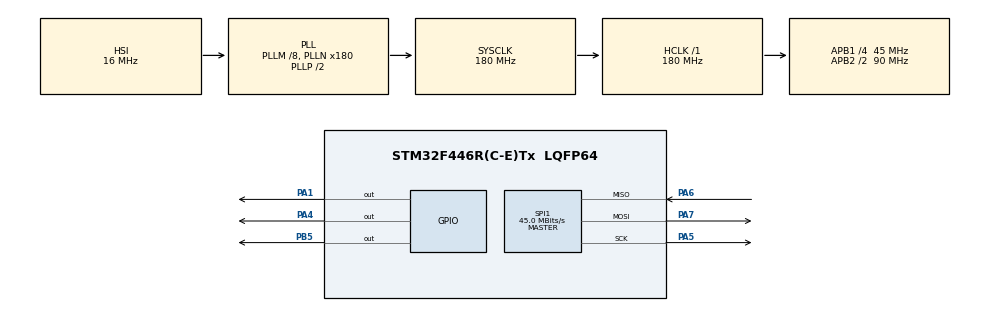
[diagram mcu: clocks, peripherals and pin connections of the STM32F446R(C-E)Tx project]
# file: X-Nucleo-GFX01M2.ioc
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Mcu.Family=STM32F4
Mcu.Name=STM32F446R(C-E)Tx
Mcu.Package=LQFP64
NVIC.PriorityGroup=NVIC_PRIORITYGROUP_4
PA1.GPIO_Speed=GPIO_SPEED_FREQ_VERY_HIGH
PA1.PinState=GPIO_PIN_SET
PA1.Signal=GPIO_Output
PA13.Mode=Serial_Wire
PA13.Signal=SYS_JTMS-SWDIO
PA14.Mode=Serial_Wire
PA14.Signal=SYS_JTCK-SWCLK
PA4.GPIO_Speed=GPIO_SPEED_FREQ_VERY_HIGH
PA4.Signal=GPIO_Output
PA5.Mode=Full_Duplex_Master
PA5.Signal=SPI1_SCK
PA6.Mode=Full_Duplex_Master
PA6.Signal=SPI1_MISO
PA7.Mode=Full_Duplex_Master
PA7.Signal=SPI1_MOSI
PB5.GPIO_Speed=GPIO_SPEED_FREQ_VERY_HIGH
PB5.PinState=GPIO_PIN_SET
PB5.Signal=GPIO_Output
ProjectManager.HeapSize=0x200
ProjectManager.StackSize=0x400
ProjectManager.TargetToolchain=MDK-ARM V5.32
RCC.AHBFreq_Value=180000000
RCC.APB1CLKDivider=RCC_HCLK_DIV4
RCC.APB1Freq_Value=45000000
RCC.APB1TimFreq_Value=90000000
RCC.APB2CLKDivider=RCC_HCLK_DIV2
RCC.APB2Freq_Value=90000000
RCC.APB2TimFreq_Value=180000000
RCC.CortexFreq_Value=180000000
RCC.HCLKFreq_Value=180000000
RCC.PLLM=8
RCC.PLLN=180
RCC.SYSCLKFreq_VALUE=180000000
RCC.SYSCLKSource=RCC_SYSCLKSOURCE_PLLCLK
RCC.USBFreq_Value=180000000
RCC.VCOOutputFreq_Value=360000000
SPI1.BaudRatePrescaler=SPI_BAUDRATEPRESCALER_2
SPI1.CalculateBaudRate=45.0 MBits/s
SPI1.Direction=SPI_DIRECTION_2LINES
SPI1.Mode=SPI_MODE_MASTER
SPI1.VirtualType=VM_MASTER
board=custom

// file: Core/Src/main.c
/* USER CODE BEGIN Header */
/**
  ******************************************************************************
  * @file           : main.c
  * @brief          : Main program body
  ******************************************************************************
  * @attention
  *
  * Copyright (c) 2026 STMicroelectronics.
  * All rights reserved.
  *
  * This software is licensed under terms that can be found in the LICENSE file
  * in the root directory of this software component.
  * If no LICENSE file comes with this software, it is provided AS-IS.
  *
  ******************************************************************************
  */
/* USER CODE END Header */
#include "main.h"
#include "spi.h"
#include "gpio.h"

/* USER CODE BEGIN Includes */
#include "st7789h2.h"
/* USER CODE END Includes */

void SystemClock_Config(void);

int main(void)
{

  /* MCU Configuration--------------------------------------------------------*/

  /* Reset of all peripherals, Initializes the Flash interface and the Systick. */
  HAL_Init();

  /* Configure the system clock */
  SystemClock_Config();

  /* Initialize all configured peripherals */
  MX_GPIO_Init();
  MX_SPI1_Init();
  /* USER CODE BEGIN 2 */

	ST7789H2_Init();
  ST7789H2_Fill(0x0000);

//Write ASCII character (x, y, character, color, background color, letter scaling)
//ST7789H2_DrawCharScaled(50, 50, 'H', 0xFFFF, 0x0000,1);

//Write ASCII strings (x, y, string, color, letter background color, letter scaling)
ST7789H2_DrawStringScaled(50, 50, "Hello World!\n\nJust a Test\n\nTo see\n\nIf it works", 0xFFFF, 0x0000,2);

//for(int i = 0; i < 50; i++)
//{
//    ST7789H2_DrawPixel(10 + i, 10, 0x0000);   // horizontal line
//}

  /* USER CODE END 2 */

  /* Infinite loop */
  while (1)
  {

  }
}

void SystemClock_Config(void)
{
  RCC_OscInitTypeDef RCC_OscInitStruct = {0};
  RCC_ClkInitTypeDef RCC_ClkInitStruct = {0};

  /** Configure the main internal regulator output voltage
  */
  __HAL_RCC_PWR_CLK_ENABLE();
  __HAL_PWR_VOLTAGESCALING_CONFIG(PWR_REGULATOR_VOLTAGE_SCALE1);

  /** Initializes the RCC Oscillators according to the specified parameters
  * in the RCC_OscInitTypeDef structure.
  */
  RCC_OscInitStruct.OscillatorType = RCC_OSCILLATORTYPE_HSI;
  RCC_OscInitStruct.HSIState = RCC_HSI_ON;
  RCC_OscInitStruct.HSICalibrationValue = RCC_HSICALIBRATION_DEFAULT;
  RCC_OscInitStruct.PLL.PLLState = RCC_PLL_ON;
  RCC_OscInitStruct.PLL.PLLSource = RCC_PLLSOURCE_HSI;
  RCC_OscInitStruct.PLL.PLLM = 8;
  RCC_OscInitStruct.PLL.PLLN = 180;
  RCC_OscInitStruct.PLL.PLLP = RCC_PLLP_DIV2;
  RCC_OscInitStruct.PLL.PLLQ = 2;
  RCC_OscInitStruct.PLL.PLLR = 2;
  if (HAL_RCC_OscConfig(&RCC_OscInitStruct) != HAL_OK)
  {
    Error_Handler();
  }

  /** Activate the Over-Drive mode
  */
  if (HAL_PWREx_EnableOverDrive() != HAL_OK)
  {
    Error_Handler();
  }

  /** Initializes the CPU, AHB and APB buses clocks
  */
  RCC_ClkInitStruct.ClockType = RCC_CLOCKTYPE_HCLK|RCC_CLOCKTYPE_SYSCLK
                              |RCC_CLOCKTYPE_PCLK1|RCC_CLOCKTYPE_PCLK2;
  RCC_ClkInitStruct.SYSCLKSource = RCC_SYSCLKSOURCE_PLLCLK;
  RCC_ClkInitStruct.AHBCLKDivider = RCC_SYSCLK_DIV1;
  RCC_ClkInitStruct.APB1CLKDivider = RCC_HCLK_DIV4;
  RCC_ClkInitStruct.APB2CLKDivider = RCC_HCLK_DIV2;

  if (HAL_RCC_ClockConfig(&RCC_ClkInitStruct, FLASH_LATENCY_5) != HAL_OK)
  {
    Error_Handler();
  }
}

void Error_Handler(void)
{
  __disable_irq();
  while (1)
  {
  }
}
